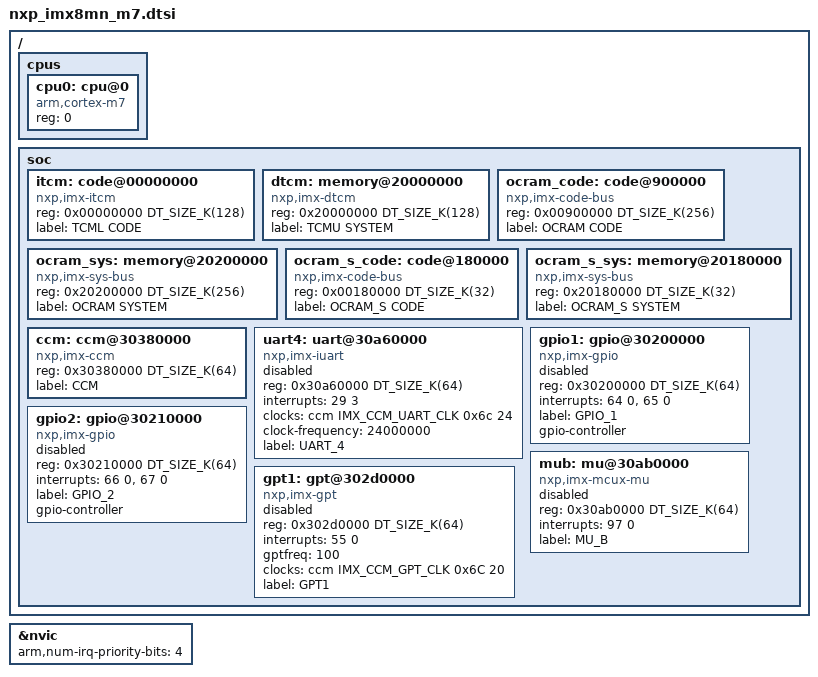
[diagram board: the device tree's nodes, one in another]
/*
 * Copyright (c) 2019, Manivannan Sadhasivam
 *
 * SPDX-License-Identifier: Apache-2.0
 */

#include <arm/armv7-m.dtsi>
#include <dt-bindings/clock/imx_ccm.h>
#include <dt-bindings/rdc/imx_rdc.h>
#include <mem.h>
#include <dt-bindings/gpio/gpio.h>

/ {
	cpus {
		#address-cells = <1>;
		#size-cells = <0>;

		cpu0: cpu@0 {
			device_type = "cpu";
			compatible = "arm,cortex-m7";
			reg = <0>;

		};
	};
	
	soc {
		itcm: code@00000000 {
			compatible = "nxp,imx-itcm";
			reg = <0x00000000 DT_SIZE_K(128)>;
			label = "TCML CODE";
		};

		dtcm: memory@20000000 {
			compatible = "nxp,imx-dtcm";
			reg = <0x20000000 DT_SIZE_K(128)>;
			label = "TCMU SYSTEM";
		};

		ocram_code: code@900000 {
			compatible = "nxp,imx-code-bus";
			reg = <0x00900000 DT_SIZE_K(256)>;
			label = "OCRAM CODE";
		};

		ocram_sys: memory@20200000 {
			device_type = "memory";
			compatible = "nxp,imx-sys-bus";
			reg = <0x20200000 DT_SIZE_K(256)>;
			label = "OCRAM SYSTEM";
		};

		ocram_s_code: code@180000 {
			compatible = "nxp,imx-code-bus";
			reg = <0x00180000 DT_SIZE_K(32)>;
			label = "OCRAM_S CODE";
		};

		ocram_s_sys: memory@20180000 {
			device_type = "memory";
			compatible = "nxp,imx-sys-bus";
			reg = <0x20180000 DT_SIZE_K(32)>;
			label = "OCRAM_S SYSTEM";
		};

		ccm: ccm@30380000 {
			compatible = "nxp,imx-ccm";
			reg = <0x30380000 DT_SIZE_K(64)>;
			label = "CCM";
			#clock-cells = <3>;
		};

		/*
		 * For now only UART4 is supported and
		 * tested with the serial driver
		 */
		uart4: uart@30a60000 {
			compatible = "nxp,imx-iuart";
			reg = <0x30a60000 DT_SIZE_K(64)>;
			interrupts = <29 3>;
			clocks = <&ccm IMX_CCM_UART_CLK 0x6c 24>;
			clock-frequency = <24000000>;
			label = "UART_4";
			status = "disabled";
		};
		
		gpio1: gpio@30200000 {
			compatible = "nxp,imx-gpio";
			reg = <0x30200000 DT_SIZE_K(64)>;
			interrupts = <64 0>, <65 0>;
			label = "GPIO_1";
			gpio-controller;
			#gpio-cells = <2>;
			status = "disabled";
		};
				
		gpio2: gpio@30210000 {
			compatible = "nxp,imx-gpio";
			reg = <0x30210000 DT_SIZE_K(64)>;
			interrupts = <66 0>, <67 0>;
			label = "GPIO_2";
			gpio-controller;
			#gpio-cells = <2>;
			status = "disabled";
		};
		mub: mu@30ab0000 {
			compatible = "nxp,imx-mcux-mu";
			reg = <0x30ab0000 DT_SIZE_K(64)>;
			interrupts = <97 0>;
			label = "MU_B";
			/*rdc = <RDC_DOMAIN_PERM(M7_DOMAIN_ID,\
		       RDC_DOMAIN_PERM_RW)>;*/
			status = "disabled";
		};
		gpt1: gpt@302d0000 {
			compatible = "nxp,imx-gpt";
			reg = <0x302d0000 DT_SIZE_K(64)>;
			interrupts = <55 0>;
			gptfreq = <100>;
			clocks = <&ccm IMX_CCM_GPT_CLK 0x6C 20>;
			label = "GPT1";
			status = "disabled";
		};

	};
};

&nvic {
	arm,num-irq-priority-bits = <4>;
};
